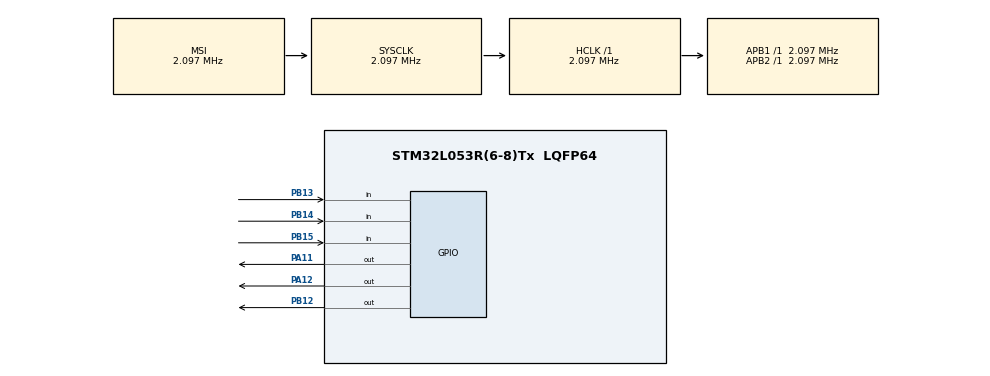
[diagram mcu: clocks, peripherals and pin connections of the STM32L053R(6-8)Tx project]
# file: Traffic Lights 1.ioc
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Mcu.Family=STM32L0
Mcu.Name=STM32L053R(6-8)Tx
Mcu.Package=LQFP64
PA11.Signal=GPIO_Output
PA12.Signal=GPIO_Output
PB12.Signal=GPIO_Output
PB13.Signal=GPIO_Input
PB14.Signal=GPIO_Input
PB15.Signal=GPIO_Input
ProjectManager.HeapSize=0x200
ProjectManager.StackSize=0x400
ProjectManager.TargetToolchain=STM32CubeIDE
RCC.AHBFreq_Value=2097000
RCC.APB1Freq_Value=2097000
RCC.APB1TimFreq_Value=2097000
RCC.APB2Freq_Value=2097000
RCC.APB2TimFreq_Value=2097000
RCC.HSE_VALUE=8000000
RCC.HSI16_VALUE=16000000
RCC.HSI48_VALUE=48000000
RCC.HSI_VALUE=16000000
RCC.LSE_VALUE=32768
RCC.MSI_VALUE=2097000
RCC.SYSCLKFreq_VALUE=2097000
RCC.VCOOutputFreq_Value=48000000
board=custom

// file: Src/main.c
/* USER CODE BEGIN Header */
/**
  ******************************************************************************
  * @file           : main.c
  * @brief          : Main program body
  ******************************************************************************
  * @attention
  *
  * <h2><center>&copy; Copyright (c) 2019 STMicroelectronics.
  * All rights reserved.</center></h2>
  *
  * This software component is licensed by ST under BSD 3-Clause license,
  * the "License"; You may not use this file except in compliance with the
  * License. You may obtain a copy of the License at:
  *                        opensource.org/licenses/BSD-3-Clause
  *
  ******************************************************************************
  */
/* USER CODE END Header */

#include "main.h"

void SystemClock_Config(void);
static void MX_GPIO_Init(void);

int main(void)
{

  /* MCU Configuration--------------------------------------------------------*/

  /* Reset of all peripherals, Initializes the Flash interface and the Systick. */
  HAL_Init();

  /* Configure the system clock */
  SystemClock_Config();

  /* Initialize all configured peripherals */
  MX_GPIO_Init();
  /* USER CODE BEGIN 2 */
  int i; // Will be later used in loop.
  int counts[3] = {0, 0, 0}; // Store button press counts.
  HAL_GPIO_WritePin(GPIOA, GPIO_PIN_12, GPIO_PIN_SET); // Set RED Led
  HAL_GPIO_WritePin(GPIOA, GPIO_PIN_11, GPIO_PIN_SET); // Set YELLOW Led
  HAL_GPIO_WritePin(GPIOB, GPIO_PIN_12, GPIO_PIN_SET); // Set GREEN Led
  /* USER CODE END 2 */

  /* Infinite loop */
  while (1)
  {
	  if(HAL_GPIO_ReadPin(GPIOB, GPIO_PIN_13) == GPIO_PIN_RESET){
		  counts[0]++; // If button 1 presses increment its own count.
		  HAL_Delay(300); // Avoid switch bouncing.
	  }
	  if(HAL_GPIO_ReadPin(GPIOB, GPIO_PIN_14) == GPIO_PIN_RESET){
		  counts[1]++; // If button 2 presses increment its own count.
		  HAL_Delay(300); // Avoid switch bouncing.
	  }
	  if(HAL_GPIO_ReadPin(GPIOB, GPIO_PIN_15) == GPIO_PIN_RESET){
		  counts[2]++; // If button 3 presses increment its count.
		  HAL_Delay(300); // Avoid switch bouncing.
	  }
	  if(counts[0] == 5){
		  // If button 1 pressed 5 times blink 2 times (100 ms on-off periods)
		  for(i = 1;i < 2;i++){
			  HAL_GPIO_TogglePin(GPIOB, GPIO_PIN_12);
			  HAL_Delay(100);
			  HAL_GPIO_TogglePin(GPIOB, GPIO_PIN_12);
			  HAL_Delay(100);
		  }
		  HAL_GPIO_TogglePin(GPIOB, GPIO_PIN_12);
		  HAL_Delay(100);
		  HAL_GPIO_TogglePin(GPIOB, GPIO_PIN_12);
		  // Reset count.
		  counts[0] = 0;
	  }
	  if(counts[1] == 4){
		  // If button 2 pressed 4 times blink 3 times (200 ms on - 100 ms off periods)
		  for(i = 1;i < 3;i++){
			  HAL_GPIO_TogglePin(GPIOA, GPIO_PIN_11);
			  HAL_Delay(200);
			  HAL_GPIO_TogglePin(GPIOA, GPIO_PIN_11);
			  HAL_Delay(100);
		  }
		  HAL_GPIO_TogglePin(GPIOA, GPIO_PIN_11);
		  HAL_Delay(200);
		  HAL_GPIO_TogglePin(GPIOA, GPIO_PIN_11);
		  // Reset count.
		  counts[1] = 0;
	  }
	  if(counts[2] == 6){
		  // If button 3 pressed 6 times blink 4 times (150 ms on - 250 ms off periods)
		  for(i = 1;i < 4;i++){
			  HAL_GPIO_TogglePin(GPIOA, GPIO_PIN_12);
			  HAL_Delay(150);
			  HAL_GPIO_TogglePin(GPIOA, GPIO_PIN_12);
			  HAL_Delay(250);
		  }
		  HAL_GPIO_TogglePin(GPIOA, GPIO_PIN_12);
		  HAL_Delay(150);
		  HAL_GPIO_TogglePin(GPIOA, GPIO_PIN_12);
		  counts[2] = 0;
	  }
  }
}

void SystemClock_Config(void)
{
  RCC_OscInitTypeDef RCC_OscInitStruct = {0};
  RCC_ClkInitTypeDef RCC_ClkInitStruct = {0};

  /** Configure the main internal regulator output voltage
  */
  __HAL_PWR_VOLTAGESCALING_CONFIG(PWR_REGULATOR_VOLTAGE_SCALE1);
  /** Initializes the CPU, AHB and APB busses clocks
  */
  RCC_OscInitStruct.OscillatorType = RCC_OSCILLATORTYPE_MSI;
  RCC_OscInitStruct.MSIState = RCC_MSI_ON;
  RCC_OscInitStruct.MSICalibrationValue = 0;
  RCC_OscInitStruct.MSIClockRange = RCC_MSIRANGE_5;
  RCC_OscInitStruct.PLL.PLLState = RCC_PLL_NONE;
  if (HAL_RCC_OscConfig(&RCC_OscInitStruct) != HAL_OK)
  {
    Error_Handler();
  }
  /** Initializes the CPU, AHB and APB busses clocks
  */
  RCC_ClkInitStruct.ClockType = RCC_CLOCKTYPE_HCLK|RCC_CLOCKTYPE_SYSCLK
                              |RCC_CLOCKTYPE_PCLK1|RCC_CLOCKTYPE_PCLK2;
  RCC_ClkInitStruct.SYSCLKSource = RCC_SYSCLKSOURCE_MSI;
  RCC_ClkInitStruct.AHBCLKDivider = RCC_SYSCLK_DIV1;
  RCC_ClkInitStruct.APB1CLKDivider = RCC_HCLK_DIV1;
  RCC_ClkInitStruct.APB2CLKDivider = RCC_HCLK_DIV1;

  if (HAL_RCC_ClockConfig(&RCC_ClkInitStruct, FLASH_LATENCY_0) != HAL_OK)
  {
    Error_Handler();
  }
}

static void MX_GPIO_Init(void)
{
  GPIO_InitTypeDef GPIO_InitStruct = {0};

  /* GPIO Ports Clock Enable */
  __HAL_RCC_GPIOB_CLK_ENABLE();
  __HAL_RCC_GPIOA_CLK_ENABLE();

  /*Configure GPIO pin Output Level */
  HAL_GPIO_WritePin(GPIOB, GPIO_PIN_12, GPIO_PIN_RESET);

  /*Configure GPIO pin Output Level */
  HAL_GPIO_WritePin(GPIOA, GPIO_PIN_11|GPIO_PIN_12, GPIO_PIN_RESET);

  /*Configure GPIO pin : PB12 */
  GPIO_InitStruct.Pin = GPIO_PIN_12;
  GPIO_InitStruct.Mode = GPIO_MODE_OUTPUT_PP;
  GPIO_InitStruct.Pull = GPIO_NOPULL;
  GPIO_InitStruct.Speed = GPIO_SPEED_FREQ_LOW;
  HAL_GPIO_Init(GPIOB, &GPIO_InitStruct);

  /*Configure GPIO pins : PB13 PB14 PB15 */
  GPIO_InitStruct.Pin = GPIO_PIN_13|GPIO_PIN_14|GPIO_PIN_15;
  GPIO_InitStruct.Mode = GPIO_MODE_INPUT;
  GPIO_InitStruct.Pull = GPIO_NOPULL;
  HAL_GPIO_Init(GPIOB, &GPIO_InitStruct);

  /*Configure GPIO pins : PA11 PA12 */
  GPIO_InitStruct.Pin = GPIO_PIN_11|GPIO_PIN_12;
  GPIO_InitStruct.Mode = GPIO_MODE_OUTPUT_PP;
  GPIO_InitStruct.Pull = GPIO_NOPULL;
  GPIO_InitStruct.Speed = GPIO_SPEED_FREQ_LOW;
  HAL_GPIO_Init(GPIOA, &GPIO_InitStruct);

}

void Error_Handler(void)
{
}

/************************ (C) COPYRIGHT STMicroelectronics *****END OF FILE****/
